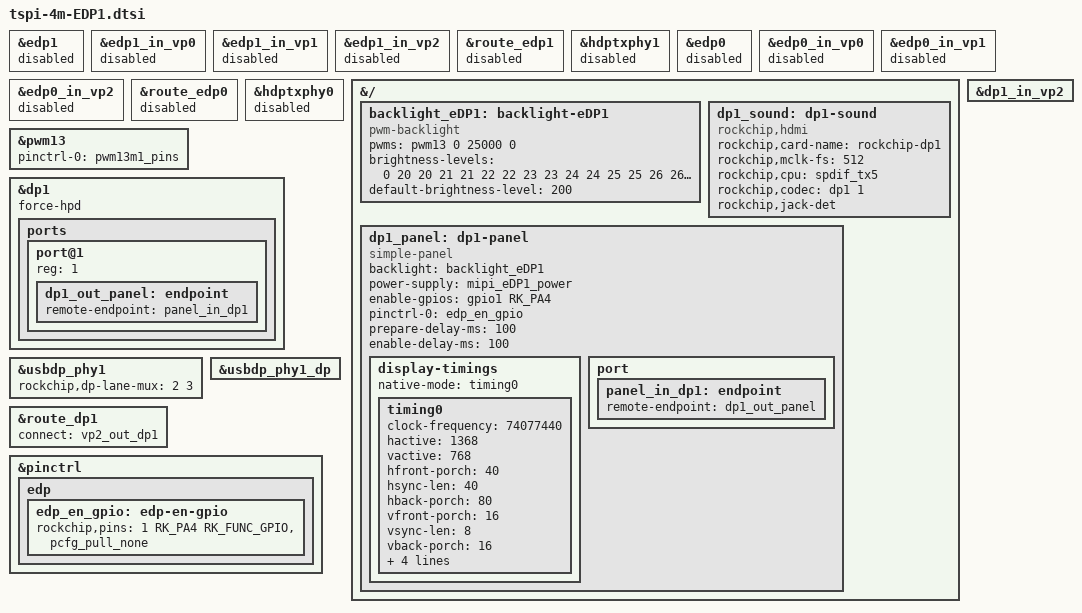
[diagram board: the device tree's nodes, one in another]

#define TSPI_eDP_TX1


/******************** EDP TX1 ********************/
// Disable edp1 and use dp1.
&edp1 {
	status = "disabled";
};

&edp1_in_vp0 {
	status = "disabled";
};

&edp1_in_vp1 {
	status = "disabled";
};

&edp1_in_vp2 {
	status = "disabled";
};

&route_edp1 {
	status = "disabled";
};

&hdptxphy1 {
	status = "disabled";
};


/******************** EDP TX0 ********************/
&edp0 {
	status = "disabled";
};

&edp0_in_vp0 {
	status = "disabled";
};

&edp0_in_vp1 {
	status = "disabled";
};

&edp0_in_vp2 {
	status = "disabled";
};

&route_edp0 {
	status = "disabled";
};

&hdptxphy0 {
	status = "disabled";
};



#if defined(TSPI_eDP_TX1)


&{/} {
	backlight_eDP1: backlight-eDP1 {
		compatible = "pwm-backlight";
		pwms = <&pwm13 0 25000 0>;
		brightness-levels = <
		0  20  20  21  21  22  22  23
		23  24  24  25  25  26  26  27
		27  28  28  29  29  30  30  31
		31  32  32  33  33  34  34  35
		35  36  36  37  37  38  38  39
		40  41  42  43  44  45  46  47
		48  49  50  51  52  53  54  55
		56  57  58  59  60  61  62  63
		64  65  66  67  68  69  70  71
		72  73  74  75  76  77  78  79
		80  81  82  83  84  85  86  87
		88  89  90  91  92  93  94  95
		96  97  98  99 100 101 102 103
		104 105 106 107 108 109 110 111
		112 113 114 115 116 117 118 119
		120 121 122 123 124 125 126 127
		128 129 130 131 132 133 134 135
		136 137 138 139 140 141 142 143
		144 145 146 147 148 149 150 151
		152 153 154 155 156 157 158 159
		160 161 162 163 164 165 166 167
		168 169 170 171 172 173 174 175
		176 177 178 179 180 181 182 183
		184 185 186 187 188 189 190 191
		192 193 194 195 196 197 198 199
		200 201 202 203 204 205 206 207
		208 209 210 211 212 213 214 215
		216 217 218 219 220 221 222 223
		224 225 226 227 228 229 230 231
		232 233 234 235 236 237 238 239
		240 241 242 243 244 245 246 247
		248 249 250 251 252 253 254 255
		>;
		default-brightness-level = <200>;
	};

	dp1_sound: dp1-sound {
		status = "okay";
		compatible = "rockchip,hdmi";
		rockchip,card-name= "rockchip-dp1";
		rockchip,mclk-fs = <512>;
		rockchip,cpu = <&spdif_tx5>;
		rockchip,codec = <&dp1 1>;
		rockchip,jack-det;
	};

	dp1_panel: dp1-panel {
		status = "okay";
		compatible = "simple-panel";
		backlight = <&backlight_eDP1>;
		power-supply = <&mipi_eDP1_power>;
		enable-gpios = <&gpio1 RK_PA4 GPIO_ACTIVE_HIGH>;
		pinctrl-names = "default";
		pinctrl-0 = <&edp_en_gpio>;

		// Delay AUX communication as in the working reference configuration.
		prepare-delay-ms = <100>;
		enable-delay-ms = <100>;


		display-timings {
			native-mode = <&timing0>;

			timing0: timing0 {
				// Use exactly 60 Hz to match HDMI and prevent ghosting during dragging.
				// 74077440 = 60 * 1528 * 808; the original 72.3 MHz clock gives 58.56 Hz.
				clock-frequency = <74077440>;
				hactive = <1368>;
				vactive = <768>;
				// Horizontal timing
				hfront-porch = <40>;
				hsync-len = <40>;
				hback-porch = <80>;
				// Vertical timing
				vfront-porch = <16>;
				vsync-len = <8>;
				vback-porch = <16>;
				hsync-active = <0>;
				vsync-active = <0>;
				de-active = <0>;
				pixelclk-active = <0>;
			};
		};

		port {
			panel_in_dp1: endpoint {
				remote-endpoint = <&dp1_out_panel>;
			};
		};
	};
};

&pwm13 {
	pinctrl-0 = <&pwm13m1_pins>;
	status = "okay";
};

&dp1 {
	force-hpd;
	status = "okay";
	ports {
		#address-cells = <1>;
		#size-cells = <0>;
		port@1 {
			reg = <1>;

			dp1_out_panel: endpoint {
				remote-endpoint = <&panel_in_dp1>;
			};
		};
	};
};

&usbdp_phy1 {
	// The board connects two lanes: lanes 2 and 3.
	rockchip,dp-lane-mux = <2 3>;
};

&usbdp_phy1_dp {
	status = "okay";
};

&route_dp1 {
	status = "okay";
	connect = <&vp2_out_dp1>;
};

&dp1_in_vp2 {
	status = "okay";
};


// /* DP1 (eDP) needs an exact pixel clock. Set the VP1 dclk parent to v0pll (VOP PLL).
//  * With other parents, rockchip_rk3588_drm_dclk_round_rate() uses clk_round_rate() and returns an approximate rate.
//  * vop2 mode_valid then rejects all DP modes with CLOCK_RANGE, including 1368x768 at 72.3 MHz.
//  * The &vop assigned-clocks properties replace the whole group. Keep the existing ACLK_VOP = 750 MHz setting.
//  */
// &vop {
// 	assigned-clocks = <&cru ACLK_VOP>,
// 			  <&cru DCLK_VOP2>,
// 			  <&cru DCLK_VOP2_SRC>;
// 	assigned-clock-parents = <0>,
// 				 <&cru DCLK_VOP2_SRC>,
// 				 <&cru PLL_V0PLL>;
// 	assigned-clock-rates = <750000000>, <0>, <0>;
// };


&pinctrl {
	edp {
		edp_en_gpio: edp-en-gpio {
			rockchip,pins = <1 RK_PA4 RK_FUNC_GPIO &pcfg_pull_none>;
		};
	};
};

#endif
